VERSION ""

NS_ :

BS_:

BU_:

BO_ 256 WHEEL_SPEED_1: 8 ABS
 SG_ wheelSpeed_FR : 16|16@1+ (0.01,0.0) [0|655.35] "km/h"  TCU
 SG_ wheelSpeed_FL : 0|16@1+ (0.01,0.0) [0|655.35] "km/h"  TCU

BO_ 257 WHEEL_SPEED_2: 8 ABS
 SG_ wheelSpeed_RR : 16|16@1+ (0.01,0.0) [0|655.35] "km/h"  TCU
 SG_ wheelSpeed_RL : 0|16@1+ (0.01,0.0) [0|655.35] "km/h"  TCU

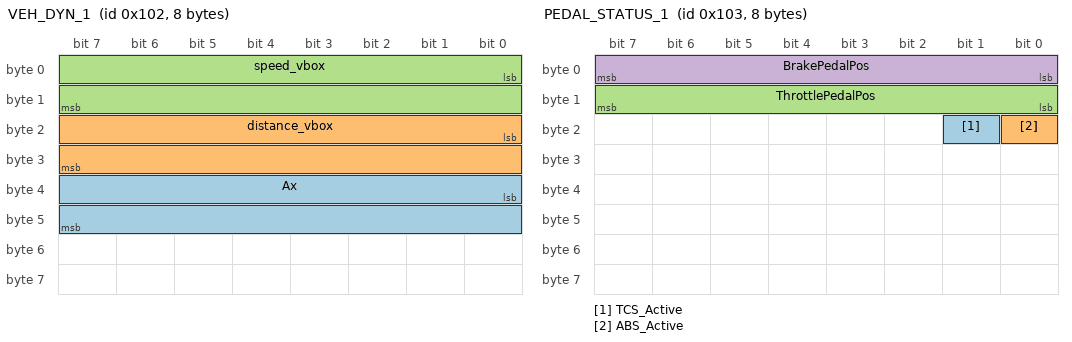
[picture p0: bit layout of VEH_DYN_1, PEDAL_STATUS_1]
BO_ 258 VEH_DYN_1: 8 ESP
 SG_ Ax : 32|16@1- (0.01,0.0) [-327.68|327.67] "m/s2"  TCU
 SG_ distance_vbox : 16|16@1+ (0.05,0.0) [0|3276.75] "m"  TCU
 SG_ speed_vbox : 0|16@1+ (0.01,0.0) [0|655.35] "km/h"  TCU

BO_ 259 PEDAL_STATUS_1: 8 VCU
 SG_ TCS_Active : 17|1@1+ (1.0,0.0) [0|0] ""  TCU
 SG_ ABS_Active : 16|1@1+ (1.0,0.0) [0|0] ""  TCU
 SG_ ThrottlePedalPos : 8|8@1+ (0.5,0.0) [0|127.5] "%"  TCU
 SG_ BrakePedalPos : 0|8@1+ (0.5,0.0) [0|127.5] "%"  TCU

BO_ 260 VEH_DYN_2: 8 ESP
 SG_ yaw_rate : 0|16@1- (0.01,0.0) [-327.68|327.67] "deg/s"  TCU

BO_ 261 DRIVE_TYPE: 8 VCU
 SG_ VehDriveType : 0|8@1+ (1.0,0.0) [0|255] ""  TCU

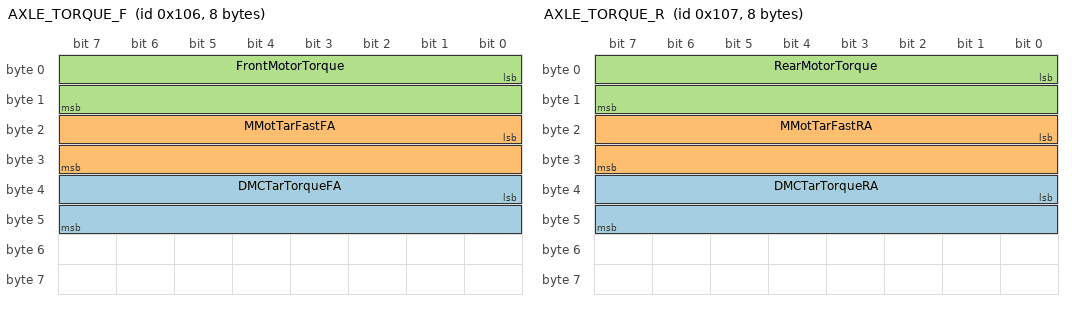
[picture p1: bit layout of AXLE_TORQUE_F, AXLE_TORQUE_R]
BO_ 262 AXLE_TORQUE_F: 8 MCU_F
 SG_ DMCTarTorqueFA : 32|16@1- (0.1,0.0) [-3276.8|3276.7] "N.m"  TCU
 SG_ MMotTarFastFA : 16|16@1- (0.1,0.0) [-3276.8|3276.7] "N.m"  TCU
 SG_ FrontMotorTorque : 0|16@1- (0.1,0.0) [-3276.8|3276.7] "N.m"  TCU

BO_ 263 AXLE_TORQUE_R: 8 MCU_R
 SG_ DMCTarTorqueRA : 32|16@1- (0.1,0.0) [-3276.8|3276.7] "N.m"  TCU
 SG_ MMotTarFastRA : 16|16@1- (0.1,0.0) [-3276.8|3276.7] "N.m"  TCU
 SG_ RearMotorTorque : 0|16@1- (0.1,0.0) [-3276.8|3276.7] "N.m"  TCU

BO_ 264 DMC_MODE: 8 DMC
 SG_ DMCOperationModeRA : 8|8@1+ (1.0,0.0) [0|255] ""  TCU
 SG_ DMCOperationModeFA : 0|8@1+ (1.0,0.0) [0|255] ""  TCU

VAL_ 259 TCS_Active 0 "INACTIVE" 1 "ACTIVE" ;
VAL_ 259 ABS_Active 0 "INACTIVE" 1 "ACTIVE" ;
